# STC32G144K246 register map
Vendor: STC; File version: 2.0
Registers are 8-bit, read-write, no defined reset value unless marked. A register's access mark holds for its fields unless they carry their own. Offsets are from the block's base; [hi:lo] are bit positions.

## Timer17_18 — Timer17/18：共用控制、独立计数和预分频
Base 0x007EFBC8
0x00 TM17PS — 定时器17预分频寄存器
  [7:0] TM17PS — 尚未自动匹配到此字段的独立说明；请查看下方章节说明。
0x01 TM18PS — 定时器18预分频寄存器
  [7:0] TM18PS — 尚未自动匹配到此字段的独立说明；请查看下方章节说明。
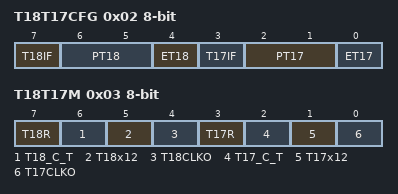
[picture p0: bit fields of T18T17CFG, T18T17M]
0x02 T18T17CFG — 定时器181/7配置寄存器
  [7] T18IF — 定时器18溢出中断标志。需软件写0清零。
  [6:5] PT18 — 定时器18中断优先级控制位
    0=定时器18 中断优先级为0 级（最低级）; 1=定时器18 中断优先级为1 级（较低级）; 2=定时器18 中断优先级为2 级（较高级）; 3=定时器18 中断优先级为3 级（最高级）
  [4] ET18 — 定时/计数器T18 的溢出中断允许位。
    0=禁止T18 中断; 1=允许T18 中断
  [3] T17IF — 定时器17溢出中断标志。需软件写0清零。
  [2:1] PT17 — 定时器17中断优先级控制位
    0=定时器17 中断优先级为0 级（最低级）; 1=定时器17 中断优先级为1 级（较低级）; 2=定时器17 中断优先级为2 级（较高级）; 3=定时器17 中断优先级为3 级（最高级）
  [0] ET17 — 定时/计数器T17 的溢出中断允许位。
    0=禁止T17 中断; 1=允许T17 中断
0x03 T18T17M — 定时器18/17控制寄存器
  [7] T18R — 定时器18的运行控制位
    0=定时器18 停止计数; 1=定时器18 开始计数
  [6] T18_C_T — 控制定时器18用作定时器或计数器，清0则用作定时器（对内部系统时钟进行计数），置1用
  [5] T18x12 — 定时器18速度控制位
    0=12T 模式，即CPU 时钟12 分频（FOSC/12）; 1=1T 模式，即CPU 时钟不分频分频（FOSC/1）
  [4] T18CLKO — 定时器18时钟输出控制
    0=关闭时钟输出; 1=使能T18CLKO/P9.1 口的是定时器18 时钟输出功能
  [3] T17R — 定时器17的运行控制位
    0=定时器17 停止计数; 1=定时器17 开始计数
  [2] T17_C_T — 控制定时器17用作定时器或计数器，清0则用作定时器（对内部系统时钟进行计数），置1用
  [1] T17x12 — 定时器17速度控制位
    0=12T 模式，即CPU 时钟12 分频（FOSC/12）; 1=1T 模式，即CPU 时钟不分频分频（FOSC/1）
  [0] T17CLKO — 定时器17时钟输出控制
    0=关闭时钟输出; 1=使能T17CLKO/P8.1 口的是定时器17 时钟输出功能
0x04 T18H ro — 定时器18高字节
  [7:0] TMR18 — 尚未自动匹配到此字段的独立说明；请查看下方章节说明。
0x05 T18L ro — 定时器18低字节
  [7:0] TMR18 — 尚未自动匹配到此字段的独立说明；请查看下方章节说明。
0x06 T17H ro — 定时器17高字节
  [7:0] TMR17 — 尚未自动匹配到此字段的独立说明；请查看下方章节说明。
0x07 T17L ro — 定时器17低字节
  [7:0] TMR17 — 尚未自动匹配到此字段的独立说明；请查看下方章节说明。

## Timer11 — Timer11：控制、计数和预分频
Base 0x007EFE78
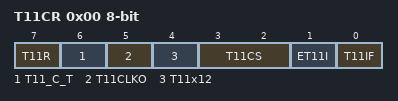
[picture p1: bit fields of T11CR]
0x00 T11CR — 定时器T11控制寄存器
  [7] T11R — 定时器T11的运行控制位
    0=定时器T11 停止计数; 1=定时器T11 开始计数
  [6] T11_C_T — 控制定时器T11用作定时器或计数器，清0则用作定时器（对内部系统时钟进行计数），置1
  [5] T11CLKO — 定时器T11时钟输出控制
    0=关闭时钟输出; 1=使能（P7.7/P1.5/PA.7/P4.5）口的是定时器T11 时钟输出功能
  [4] T11x12 — 定时器T11速度控制位
    0=12T 模式，即T11 时钟源12 分频（T11CLK/12）; 1=1T 模式，即T11 时钟源不分频分频（T11CLK /1）
  [3:2] T11CS — 定时器T11时钟源（T11CLK）选择
    0=系统时钟SYSclk; 1=内部高速IRC; 2=外部32K晶振; 3=内部低速IRC
  [1] ET11I — 定时/计数器T11 的溢出中断允许位。
    0=禁止T11 中断; 1=允许T11 中断
  [0] T11IF — T11溢出中断标志。T11被允许计数以后，从初值开始加1计数，当产生溢出时，由硬件置“1”
0x01 T11PS — 定时器T11时钟预分频寄存器
  [7:0] T11PS — 尚未自动匹配到此字段的独立说明；请查看下方章节说明。
0x02 T11H ro — 定时器T11高字节
  [7:0] TMR11 — 尚未自动匹配到此字段的独立说明；请查看下方章节说明。
0x03 T11L ro — 定时器T11低字节
  [7:0] TMR11 — 尚未自动匹配到此字段的独立说明；请查看下方章节说明。

## RTC — 实时时钟和中断
Base 0x007EFE60
0x00 RTCCR ro — RTC控制寄存器
  [0] RUNRTC — RTC 模块控制位
    0=关闭RTC，RTC 停止计数; 1=使能RTC，并开始RTC 计数
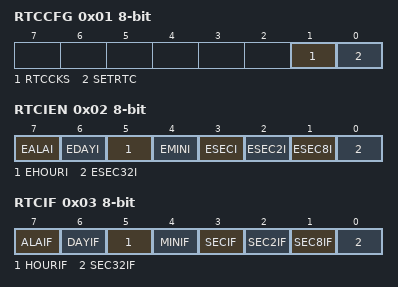
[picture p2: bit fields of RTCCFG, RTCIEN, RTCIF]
0x01 RTCCFG — RTC配置寄存器
  [1] RTCCKS — RTC 时钟源选择
    0=选择外部32.768KHz 时钟源（需先软件启动外部32K 晶振）; 1=选择内部32K 时钟源（需先软件启动内部32K 振荡器）
  [0] SETRTC — 设置RTC 初始值 写0：无意义 写1：触发RTC 寄存器初始化。当SETRTC 设置为1 时，硬件会自动将寄存器INIYEAR、INIMONTH、 INIDAY、INIWEEK、INIHOUR、INIMIN、INISEC、INISSEC 中的值复制到寄存器RTCYEAR、 RTCMONTH、RTC
0x02 RTCIEN — RTC中断使能寄存器
  [7] EALAI — 闹钟中断使能位
    0=关闭闹钟中断; 1=使能闹钟中断
  [6] EDAYI — 一日（24 小时）中断使能位
    0=关闭一日中断; 1=使能一日中断
  [5] EHOURI — 一小时（60 分钟）中断使能位
    0=关闭小时中断; 1=使能小时中断
  [4] EMINI — 一分钟（60 秒）中断使能位
    0=关闭分钟中断; 1=使能分钟中断
  [3] ESECI — 一秒中断使能位
    0=关闭秒中断; 1=使能秒中断
  [2] ESEC2I — 1/2 秒中断使能位
    0=关闭1/2 秒中断; 1=使能1/2 秒中断
  [1] ESEC8I — 1/8 秒中断使能位
    0=关闭1/8 秒中断; 1=使能1/8 秒中断
  [0] ESEC32I — 1/32 秒中断使能位
    0=关闭1/32 秒中断; 1=使能1/32 秒中断
0x03 RTCIF ro — RTC中断请求寄存器
  [7] ALAIF — 闹钟中断请求位。需软件清零。
  [6] DAYIF — 一日（24 小时）中断请求位。需软件清零。
  [5] HOURIF — 一小时（60 分钟）中断请求位。需软件清零。
  [4] MINIF — 一分钟（60 秒）中断请求位。需软件清零。
  [3] SECIF — 一秒中断请求位。需软件清零。
  [2] SEC2IF — 1/2 秒中断请求位。需软件清零
  [1] SEC8IF — 1/8 秒中断请求位。需软件清零。
  [0] SEC32IF — 1/32 秒中断请求位。需软件清零。
0x0F RTCWEEK ro — RTC的星期值
  [2:0] RTCWEEK — 当前实时时间的星期值。硬件会根据当前的年月日日期值自动计算星期。
0x10 RTCYEAR ro — RTC的年计数值
  [6:0] RTCYEAR — 当前实时时间的年值。
0x11 RTCMONTH ro — RTC的月计数值
  [3:0] RTCMONTH — 当前实时时间的月值。数字编码与MONTH 相同。
0x12 RTCDAY ro — RTC的日计数值
  [4:0] RTCDAY — 当前实时时间的日值。数字编码与DAY 相同。
0x13 RTCHOUR ro — RTC的小时计数值
  [4:0] RTCHOUR — 当前实时时间的小时值。数字编码与HOUR 相同。
0x14 RTCMIN ro — RTC的分钟计数值
  [5:0] RTCMIN — 当前实时时间的分钟值。数字编码与MIN 相同。
0x15 RTCSEC ro — RTC的秒计数值
  [5:0] RTCSEC — 当前实时时间的秒值。数字编码与SEC 相同。
0x16 RTCSSEC ro — RTC的1/128秒计数值
  [6:0] RTCSSEC — 当前实时时间的1/128 秒值。数字编码与SSEC 相同。
